VERSION ""

NS_ :

BS_:

BU_:

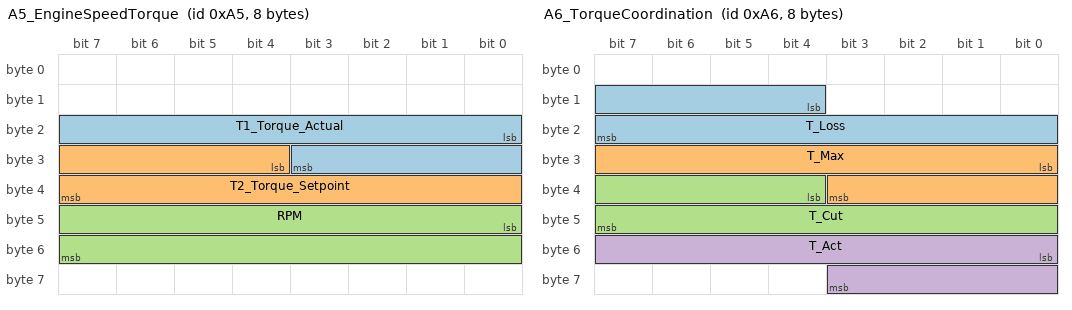
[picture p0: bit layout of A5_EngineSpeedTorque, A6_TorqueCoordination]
BO_ 165 A5_EngineSpeedTorque: 8 Vector__XXX
 SG_ T1_Torque_Actual   : 16|12@1+ (0.5,-999.5) [-999.5|1048.0] "Nm" Vector__XXX
 SG_ T2_Torque_Setpoint : 28|12@1+ (0.5,-999.5) [-999.5|1048.0] "Nm" Vector__XXX
 SG_ RPM                : 40|16@1+ (0.25,0)     [0|16383.75]    "rpm" Vector__XXX

BO_ 166 A6_TorqueCoordination: 8 Vector__XXX
 SG_ T_Loss : 12|12@1+ (0.5,-999.5) [-999.5|1048.0] "Nm" Vector__XXX
 SG_ T_Max  : 24|12@1+ (0.5,-999.5) [-999.5|1048.0] "Nm" Vector__XXX
 SG_ T_Cut  : 36|12@1+ (0.5,-999.5) [-999.5|1048.0] "Nm" Vector__XXX
 SG_ T_Act  : 48|12@1+ (0.5,-999.5) [-999.5|1048.0] "Nm" Vector__XXX

BO_ 167 A7_AirFuelManagement: 8 Vector__XXX
 SG_ T_Demand : 12|12@1+ (0.5,-999.5) [-999.5|1048.0] "Nm" Vector__XXX
 SG_ Lambda   : 32|16@1+ (3.0518e-5,0) [0|2.0]  "" Vector__XXX

BO_ 160 A0_TransTorqueBroadcast: 8 Vector__XXX
 SG_ Counter      :  0|16@1+ (1,0)        [0|65535]  ""   Vector__XXX
 SG_ T_Net        : 16|12@1+ (0.5,-999.5) [-999.5|1048.0] "Nm" Vector__XXX
 SG_ ShiftStatus  : 24|8@1+ (1,0)         [0|255]    ""   Vector__XXX
 SG_ MsgCounter   : 48|16@1+ (1,0)        [0|65535]  ""   Vector__XXX

BO_ 176 B0_TransLambdaPermission: 8 Vector__XXX
 SG_ AliveCounter :  0|16@1+ (1,0)         [0|65535]  ""  Vector__XXX
 SG_ Lambda_Max   : 32|16@1+ (3.0518e-5,0) [0|2.0]    ""  Vector__XXX
 SG_ Mode_Status  : 32|8@1+ (1,0)          [0|255]    ""  Vector__XXX

BO_ 143 X8F_LambdaSetpoint: 8 Vector__XXX
 SG_ Lambda_Soll : 16|16@1+ (3.0518e-5,0) [0|2.0] "" Vector__XXX

BO_ 217 D9_PedalPosition: 8 Vector__XXX
 SG_ Pedal_Raw : 16|12@1+ (1,0) [0|4095] "" Vector__XXX
